# SPC1169 register map
File version: 2022071043481212
CPU: cm4 r1p0, little endian, no MPU, FPU, 4 interrupt priority bits
Registers are 32-bit, read-write, reset 0x0 unless marked. A register's access mark holds for its fields unless they carry their own. Offsets are from the block's base; lines under a group give offsets from that group; [hi:lo] are bit positions; {n}, {i} and the like mark numbered series; 'fields as' and 'values as' point back to an identical list; <NAME> marks a mode.

## Memory map
0x40000000 SYSTEM size 0x100
0x40000100 POWER size 0x14
0x40000200 CLOCK size 0x40
0x40000300 PINMUX size 0xAC
0x40000400 EPWR size 0x28
0x40000500 PHCOMP size 0x28
0x40000F00 ENGR size 0x100
0x40001000 WDT0 size 0x28
0x40001100 WDT1 size 0x28
0x40001200 GPIO size 0x200
0x40001400 UART0 size 0x5C
0x40001500 SPI0 size 0x4C
0x40001600 UART1 size 0x5C
0x40001700 SPI1 size 0x4C
0x40001800 TIMER0 size 0x20
0x40001900 TIMER1 size 0x20
0x40001A00 TIMER2 size 0x20
0x40001B00 FLASHC size 0x64
0x40001C00 DMAC blocks up to offset 0x400
{0x40001C00+0x58*n} DMACH{n} size 0x58 (n=0..7)
0x40002000 PWM0 size 0x100
0x40002100 PWM1 size 0x100
0x40002200 PWM2 size 0x100
0x40002300 PWM3 size 0x100
0x40002F00 PWMCFG size 0x40
0x40003000 ADC size 0x2D0
0x40003000 COMP blocks up to offset 0x400
0x40003000 PGA blocks up to offset 0x2F4
0x40003400 ECAP size 0x3C
0x40003500 I2C size 0x70
0x40003600 CRC size 0x28
{0x40004000+0x50*n} CANMBOX{n} size 0x50 (n=0..63)
0x40005400 CAN size 0x90

## Interrupts
0 WDT1 — WDT1 Interrupt
1 MEM (SYSTEM) — MEM Interrupt
2 EPWRTZ0 (EPWR) — ePower Tripzone Interrupt 0
3 EPWRTZ1 (EPWR) — ePower Tripzone Interrupt 1
4 GPIO_LEVEL (GPIO) — GPIO Level Triggered Interrupt
5 GPIO_EDGE (GPIO) — GPIO Edge Triggered Interrupt
6 UART0 — UART0 Interrupt
7 SPI0 — SPI0 Interrupt
8 UART1 — UART1 Interrupt
9 SPI1 — SPI1 Interrupt
{n+10} CANTRG{n} (CAN) (n=0..7) — CAN Transfer Group {n} Interrupt
18 CANMISC (CAN) — CAN Miscellaneous Interrupt
19 I2C — I2C Interrupt
{n+20} ADCCH{n} (ADC) (n=0..15) — ADC Channel {n} EOC Interrupt
36 ADCPPU0 (ADC) — ADC PPU0 Interrupt
37 ADCPPU1 (ADC) — ADC PPU1 Interrupt
38 ADCPPU2 (ADC) — ADC PPU2 Interrupt
39 PHCOMP — PHCOMP Interrupt
40 PWM0 — PWM0 Interrupt
41 PWM1 — PWM1 Interrupt
42 PWM2 — PWM2 Interrupt
43 PWM3 — PWM3 Interrupt
44 PWM0TZ (PWM0) — PWM0 Tripzone Interrupt
45 PWM1TZ (PWM1) — PWM1 Tripzone Interrupt
46 PWM2TZ (PWM2) — PWM2 Tripzone Interrupt
47 PWM3TZ (PWM3) — PWM3 Tripzone Interrupt
48 ECAP — ECAP Interrupt
49 DMAC — DMAC Interrupt
50 TIMER0 — Timer 0 Interrupt
51 TIMER1 — Timer 1 Interrupt
52 TIMER2 — Timer 2 Interrupt
53 CRC — CRC Interrupt

## POWER
Base 0x40000100
0x00 LDOCTL reset 0x7 — Power Control Register
  [3:0] VOUT — 1.2V LDO output voltage. The output will be saturated at the minimum voltage when the code goes lower below certain code (usually <4). The output will be saturated at the maximum voltage when the code goes above certain code (usually>11). The exact threshold various from chip to chip.
    0=1P06_V (1.06V); 1=1P08_V (1.08V); 2=1P10_V (1.10V); 3=1P12_V (1.12V); 4=1P14_V (1.14V); 5=1P16_V (1.16V); 6=1P18_V (1.18V); 7=1P20_V (1.20V); 8=1P22_V (1.22V); 9=1P24_V (1.24V); 10=1P26_V (1.26V); 11=1P28_V (1.28V); 12=1P30_V (1.30V); 13=1P32_V (1.32V); 14=1P34_V (1.34V); 15=1P36_V (1.36V)
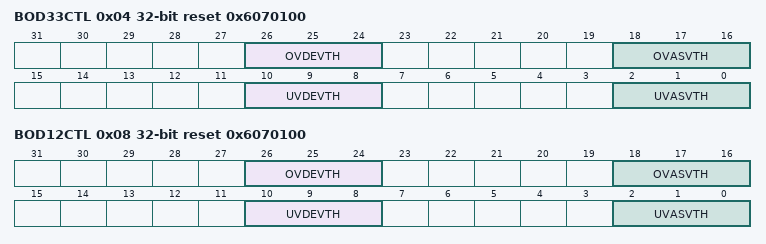
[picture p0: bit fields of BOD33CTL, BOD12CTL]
0x04 BOD33CTL reset 0x6070100 — 3.3V BOD Control Register
  [26:24] OVDEVTH — Select the threshold voltage to deassert VDD33OV when 3.3V supply is going low
    3=3P66_V (3.66V); 4=3P79_V (3.79V); 5=3P93_V (3.93V); 6=4P08_V (4.08V); 7=4P24_V (4.24V)
  [18:16] OVASVTH — Select the threshold voltage to assert VDD33OV when 3.3V supply is going high
    values as OVDEVTH
  [10:8] UVDEVTH — Select the threshold voltage to deassert VDD33UV when 3.3V supply is going high
    4=2P86V (2.86V); 5=2P94_V (2.94V); 6=3P03_V (3.03V)
  [2:0] UVASVTH — Select the threshold voltage to assert VDD33UV when 3.3V supply is going low
    4=2P86_V (2.86V); 5=2P94_V (2.94V); 6=3P03_V (3.03V)
0x08 BOD12CTL reset 0x6070100 — 1.2V BOD Control Register
  [26:24] OVDEVTH — Select the threshold voltage to deassert VDD12OV when 1.2V supply is going low
    2=1P36_V (1.36V); 3=1P38_V (1.38V); 4=1P41_V (1.41V); 5=1P43_V (1.43V); 6=1P46_V (1.46V); 7=1P49_V (1.49V)
  [18:16] OVASVTH — Select the threshold voltage to assert VDD12OV when 1.2V supply is going high
    values as OVDEVTH
  [10:8] UVDEVTH — Select the threshold voltage to deassert VDD12UV when 1.2V supply is going high
    0=0P94_V (0.94V); 1=0P97_V (0.97V); 2=0P99_V (0.99V); 3=1P02_V (1.02V); 4=1P04_V (1.04V); 5=1P07_V (1.07V)
  [2:0] UVASVTH — Select the threshold voltage to assert VDD12UV when 1.2V supply is going low
    values as UVDEVTH
0x0C PWRMODECMD — Power Mode Command Register
  [31:0] KEY — Write 0xA5A51EE9 to make the MCU go to deep-sleep. Write 0x5A5A5709 to make the MCU go to stop
0x10 PWRREGKEY reset 0x1ACCE551 — Power Register Write-Allow Key Register
  [31:0] KEY — Write 0x1ACCE551 to unlock protected power registers. Write 0xACCE55CD to unlock PWRMODECMD register

## Licence text in the file
ARM Limited (ARM) is supplying this software for use with Cortex-M processor based microcontroller, but can be equally used for other suitable processor architectures. This file can be freely distributed. Modifications to this file shall be clearly marked. . THIS SOFTWARE IS PROVIDED "AS IS". NO WARRANTIES, WHETHER EXPRESS, IMPLIED. OR STATUTORY, INCLUDING, BUT NOT LIMITED TO, IMPLIED WARRANTIES OF. MERCHANTABILITY AND FITNESS FOR A PARTICULAR PURPOSE APPLY TO THIS SOFTWARE. ARM SHALL NOT, IN ANY CIRCUMSTANCES, BE LIABLE FOR SPECIAL, INCIDENTAL, OR. CONSEQUENTIAL DAMAGES, FOR ANY REASON WHATSOEVER.

## Notices in the file
Copyright (C) 2014-2022 ARM Limited. All rights reserved.
Purpose: System Viewer Description (SVD) Example (Schema Version 1.1)
This is a description of a none-existent and incomplete device
for demonstration purposes only.
Redistribution and use in source and binary forms, with or without
modification, are permitted provided that the following conditions are met:
- Redistributions of source code must retain the above copyright
notice, this list of conditions and the following disclaimer.
- Redistributions in binary form must reproduce the above copyright
notice, this list of conditions and the following disclaimer in the
documentation and/or other materials provided with the distribution.
- Neither the name of ARM nor the names of its contributors may be used
to endorse or promote products derived from this software without
specific prior written permission.
THIS SOFTWARE IS PROVIDED BY THE COPYRIGHT HOLDERS AND CONTRIBUTORS "AS IS"
AND ANY EXPRESS OR IMPLIED WARRANTIES, INCLUDING, BUT NOT LIMITED TO, THE
ARE DISCLAIMED. IN NO EVENT SHALL COPYRIGHT HOLDERS AND CONTRIBUTORS BE
LIABLE FOR ANY DIRECT, INDIRECT, INCIDENTAL, SPECIAL, EXEMPLARY, OR
CONSEQUENTIAL DAMAGES (INCLUDING, BUT NOT LIMITED TO, PROCUREMENT OF
SUBSTITUTE GOODS OR SERVICES; LOSS OF USE, DATA, OR PROFITS; OR BUSINESS
INTERRUPTION) HOWEVER CAUSED AND ON ANY THEORY OF LIABILITY, WHETHER IN
CONTRACT, STRICT LIABILITY, OR TORT (INCLUDING NEGLIGENCE OR OTHERWISE)
ARISING IN ANY WAY OUT OF THE USE OF THIS SOFTWARE, EVEN IF ADVISED OF THE
POSSIBILITY OF SUCH DAMAGE.
